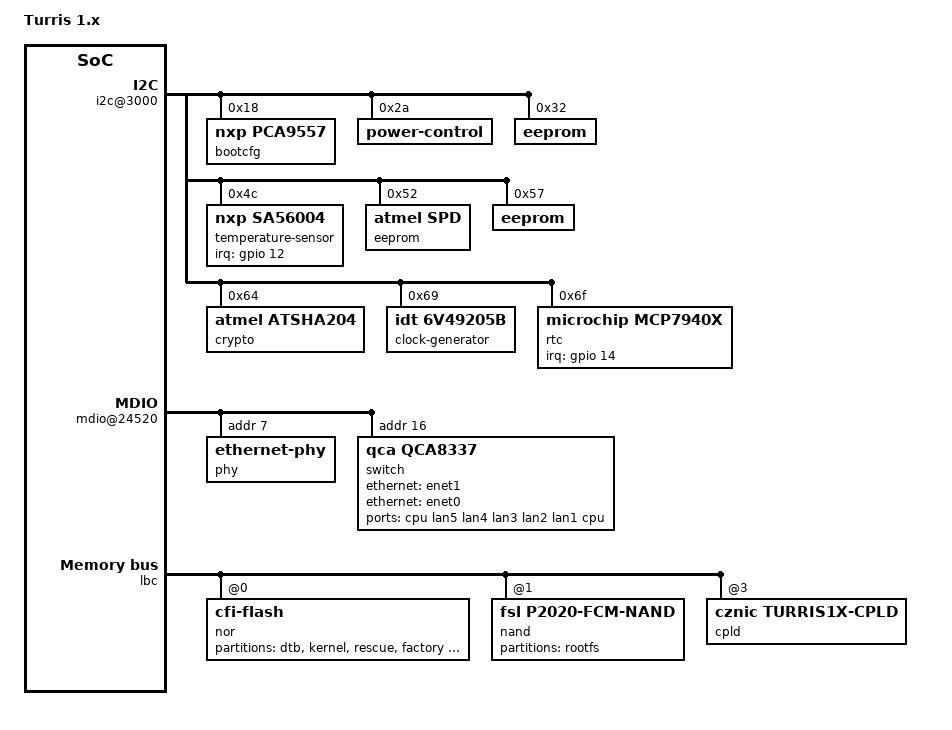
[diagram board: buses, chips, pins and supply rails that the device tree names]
#include <dt-bindings/gpio/gpio.h>
#include <dt-bindings/interrupt-controller/irq.h>
#include <dt-bindings/leds/common.h>
/include/ "fsl/p2020si-pre.dtsi"
/ {
	model = "Turris 1.x";
	compatible = "cznic,turris1x";
	aliases {
		ethernet0 = &enet0;
		ethernet1 = &enet1;
		ethernet2 = &enet2;
		serial0 = &serial0;
		serial1 = &serial1;
		pci0 = &pci0;
		pci1 = &pci1;
		pci2 = &pci2;
		spi0 = &spi0;
	};
	memory {
		device_type = "memory";
	};
	soc: soc@ffe00000 {
		ranges = <0x0 0x0 0xffe00000 0x00100000>;
		i2c@3000 {
			gpio-controller@18 {
				compatible = "nxp,pca9557";
				label = "bootcfg";
				reg = <0x18>;
				#gpio-cells = <2>;
				gpio-controller;
				polarity = <0x00>;
			};
			power-control@2a {
				reg = <0x2a>;
			};
			eeprom@32 {
				reg = <0x32>;
			};
			temperature-sensor@4c {
				compatible = "nxp,sa56004";
				reg = <0x4c>;
				interrupt-parent = <&gpio>;
				interrupts = <12 IRQ_TYPE_LEVEL_LOW>,  
					     <13 IRQ_TYPE_LEVEL_LOW>;  
				#address-cells = <1>;
				#size-cells = <0>;
				channel@0 {
					reg = <0>;
					label = "board";
				};
				channel@1 {
					reg = <1>;
					label = "cpu";
				};
			};
			eeprom@52 {
				compatible = "atmel,spd";
				reg = <0x52>;
			};
			eeprom@57 {
				reg = <0x57>;
			};
			crypto@64 {
				compatible = "atmel,atsha204";
				reg = <0x64>;
			};
			clock-generator@69 {
				compatible = "idt,6v49205b";
				reg = <0x69>;
			};
			rtc@6f {
				compatible = "microchip,mcp7940x";
				reg = <0x6f>;
				interrupt-parent = <&gpio>;
				interrupts = <14 0>;  
			};
		};
		spi0: spi@7000 {
		};
		gpio: gpio-controller@fc00 {
			#interrupt-cells = <2>;
			interrupt-controller;
		};
		usb@22000 {
			phy_type = "ulpi";
			dr_mode = "host";
		};
		enet0: ethernet@24000 {
			phy-connection-type = "rgmii-id";
			fixed-link {
				speed = <1000>;
				full-duplex;
			};
		};
		mdio@24520 {
			phy: ethernet-phy@7 {
				interrupts = <3 1 0 0>;
				reg = <0x7>;
			};
			switch@10 {
				compatible = "qca,qca8337";
				interrupts = <2 1 0 0>;
				reg = <0x10>;
				ports {
					#address-cells = <1>;
					#size-cells = <0>;
					port@0 {
						reg = <0>;
						label = "cpu";
						ethernet = <&enet1>;
						phy-mode = "rgmii-id";
						fixed-link {
							speed = <1000>;
							full-duplex;
						};
					};
					port@1 {
						reg = <1>;
						label = "lan5";
					};
					port@2 {
						reg = <2>;
						label = "lan4";
					};
					port@3 {
						reg = <3>;
						label = "lan3";
					};
					port@4 {
						reg = <4>;
						label = "lan2";
					};
					port@5 {
						reg = <5>;
						label = "lan1";
					};
					port@6 {
						reg = <6>;
						label = "cpu";
						ethernet = <&enet0>;
						phy-mode = "rgmii-id";
						fixed-link {
							speed = <1000>;
							full-duplex;
						};
					};
				};
			};
		};
		ptp_clock@24e00 {
			fsl,tclk-period = <5>;
			fsl,tmr-prsc = <200>;
			fsl,tmr-add = <0xcccccccd>;
			fsl,tmr-fiper1 = <0x3b9ac9fb>;
			fsl,tmr-fiper2 = <0x0001869b>;
			fsl,max-adj = <249999999>;
		};
		enet1: ethernet@25000 {
			phy-connection-type = "rgmii-id";
			fixed-link {
				speed = <1000>;
				full-duplex;
			};
		};
		mdio@25520 {
			status = "disabled";
		};
		enet2: ethernet@26000 {
			label = "wan";
			phy-handle = <&phy>;
			phy-connection-type = "rgmii-id";
		};
		mdio@26520 {
			status = "disabled";
		};
		sdhc@2e000 {
			bus-width = <4>;
			cd-gpios = <&gpio 8 GPIO_ACTIVE_LOW>;
		};
	};
	lbc: localbus@ffe05000 {
		reg = <0 0xffe05000 0 0x1000>;
		ranges = <0x0 0x0 0x0 0xef000000 0x01000000>,  
			 <0x1 0x0 0x0 0xff800000 0x00040000>,  
			 <0x3 0x0 0x0 0xffa00000 0x00020000>;  
		nor@0,0 {
			compatible = "cfi-flash";
			reg = <0x0 0x0 0x01000000>;
			bank-width = <2>;
			device-width = <1>;
			partitions {
				compatible = "fixed-partitions";
				#address-cells = <1>;
				#size-cells = <1>;
				partition@0 {
					reg = <0x00000000 0x00020000>;
					label = "dtb";
				};
				partition@20000 {
					reg = <0x00020000 0x001a0000>;
					label = "kernel";
				};
				partition@1c0000 {
					reg = <0x001c0000 0x00180000>;
					label = "rescue";
				};
				partition@340000 {
					reg = <0x00340000 0x00b00000>;
					label = "factory";
				};
				partition@e40000 {
					reg = <0x00e40000 0x000c0000>;
					label = "certificates";
				};
				partition@f20000 {
					reg = <0x00f20000 0x00020000>;
					label = "u-boot-env";
				};
				partition@f40000 {
					reg = <0x00f40000 0x000c0000>;
					label = "u-boot";
				};
			};
		};
		nand@1,0 {
			compatible = "fsl,p2020-fcm-nand", "fsl,elbc-fcm-nand";
			reg = <0x1 0x0 0x00040000>;
			nand-ecc-mode = "soft";
			nand-ecc-algo = "bch";
			partitions {
				compatible = "fixed-partitions";
				#address-cells = <1>;
				#size-cells = <1>;
				partition@0 {
					reg = <0x00000000 0x10000000>;
					label = "rootfs";
				};
			};
		};
		cpld@3,0 {
			compatible = "cznic,turris1x-cpld", "fsl,p1021rdb-pc-cpld", "simple-bus", "syscon";
			reg = <0x3 0x0 0x30>;
			#address-cells = <1>;
			#size-cells = <1>;
			ranges = <0x0 0x3 0x0 0x00020000>;
			watchdog@2 {
				compatible = "maxim,max6370";
				reg = <0x02 0x01>;
				gpios = <&gpio 11 GPIO_ACTIVE_LOW>;
			};
			reboot@d {
				compatible = "syscon-reboot";
				reg = <0x0d 0x01>;
				offset = <0x0d>;
				mask = <0x01>;
				value = <0x01>;
				priority = <64>;
			};
			led-controller@13 {
				compatible = "cznic,turris1x-leds";
				reg = <0x13 0x1d>;
				#address-cells = <1>;
				#size-cells = <0>;
				multi-led@0 {
					reg = <0x0>;
					color = <LED_COLOR_ID_RGB>;
					function = LED_FUNCTION_WAN;
				};
				multi-led@1 {
					reg = <0x1>;
					color = <LED_COLOR_ID_RGB>;
					function = LED_FUNCTION_LAN;
					function-enumerator = <5>;
				};
				multi-led@2 {
					reg = <0x2>;
					color = <LED_COLOR_ID_RGB>;
					function = LED_FUNCTION_LAN;
					function-enumerator = <4>;
				};
				multi-led@3 {
					reg = <0x3>;
					color = <LED_COLOR_ID_RGB>;
					function = LED_FUNCTION_LAN;
					function-enumerator = <3>;
				};
				multi-led@4 {
					reg = <0x4>;
					color = <LED_COLOR_ID_RGB>;
					function = LED_FUNCTION_LAN;
					function-enumerator = <2>;
				};
				multi-led@5 {
					reg = <0x5>;
					color = <LED_COLOR_ID_RGB>;
					function = LED_FUNCTION_LAN;
					function-enumerator = <1>;
				};
				multi-led@6 {
					reg = <0x6>;
					color = <LED_COLOR_ID_RGB>;
					function = LED_FUNCTION_WLAN;
				};
				multi-led@7 {
					reg = <0x7>;
					color = <LED_COLOR_ID_RGB>;
					function = LED_FUNCTION_POWER;
				};
			};
		};
	};
	pci2: pcie@ffe08000 {
		reg = <0 0xffe08000 0 0x1000>;
		ranges = <0x02000000 0x0 0xc0000000 0 0xc0000000 0x0 0x00020000>,  
			 <0x01000000 0x0 0x00000000 0 0xffc20000 0x0 0x00010000>;  
		pcie@0 {
			ranges;
		};
	};
	pci1: pcie@ffe09000 {
		reg = <0 0xffe09000 0 0x1000>;
		ranges = <0x02000000 0x0 0xa0000000 0 0xa0000000 0x0 0x20000000>,  
			 <0x01000000 0x0 0x00000000 0 0xffc10000 0x0 0x00010000>;  
		pcie@0 {
			ranges;
		};
	};
	pci0: pcie@ffe0a000 {
		reg = <0 0xffe0a000 0 0x1000>;
		ranges = <0x02000000 0x0 0x80000000 0 0x80000000 0x0 0x20000000>,  
			 <0x01000000 0x0 0x00000000 0 0xffc00000 0x0 0x00010000>;  
		pcie@0 {
			ranges;
		};
	};
};
/include/ "fsl/p2020si-post.dtsi"
